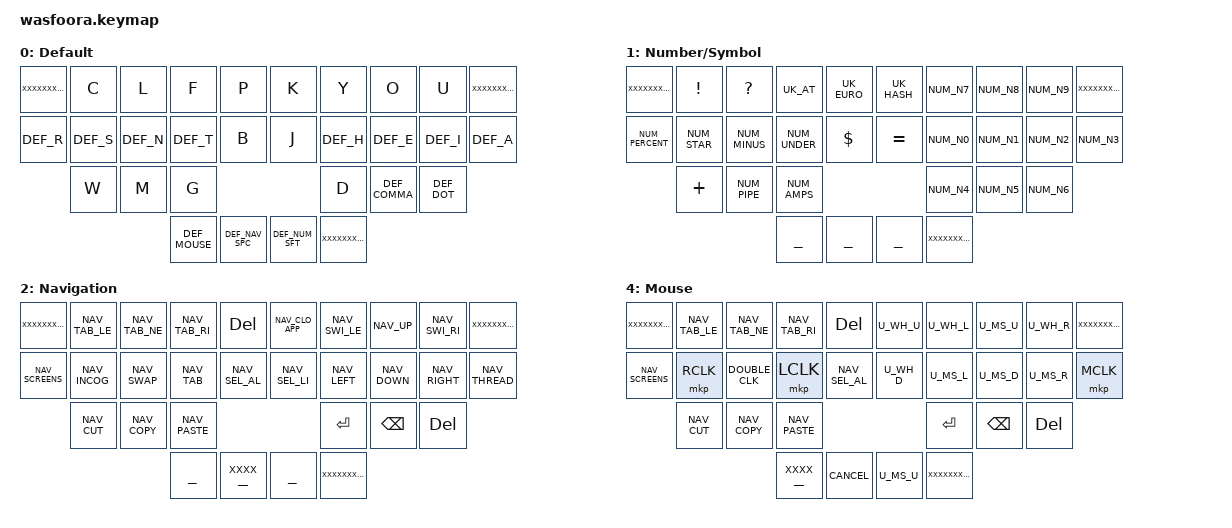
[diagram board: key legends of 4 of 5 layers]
/*					   KEY POSITIONS
 *		 0	 1	 2	 3	 4		 5	 6	 7	 8	 9
 *		10	11	12	13	14		15	16	17	18	19
 *			20	21	22				23	24	25
 *					26	27		28	29
 *
 *		 	 C	 L	 F	 P		 K	 Y	 O	 U
 *		 R	 S	 N	 T	 B		 J	 H	 E	 I	 A
 *			 W	 M	 G				 D	 ,	 .
 *					   SPACE   SHIFT
 *
 *          	 Q	                    ```
 *             V   QU                  `   ' 
 *		 	 C	 L	 F	 P		 K	 Y	 O	 U
 *		 R	 S	 N	 T	 B		 J	 H	 E	 I	 A
 *			 W	 M	 G				 D	 ,	 .
 *             X   Z                   \   /
 *               ?                       ?
 */

#include "defines.dtsi"
#include "combos.dtsi"
#include "behaviors.dtsi"
#include "mouse.dtsi"
#include "macros.dtsi"

// DELETE WORDS ETC?
// LEFT HAND - diagonal lower tab (on nav shift tab) / esc on upper
// RIGHT HAND - what is useful? .space shift
// right hand shift for DQT, home row bracket pairingscd
// maybe backspace word instead of tab?
// right shift and key next to it for ALT+SPACE left hand side for puntuation with auto enter capitals etc "DOT ENTER SHIFT", "COMMA" (make the one on the first layer "COMMA SPACE"), "DOT" (make the one on the first layer "DOT SPACE SHIFT")
// https://rndkbd.com/products/sprit-springs?variant=43822770847978 with Oil Kings
/ {
	keymap {
		compatible = "zmk,keymap";

		DEF_layer {
            display-name = "Default";
            bindings = <
				XXXXXXXXXX	&kp C		&kp L		&kp F		&kp P				&kp K		&kp Y		&kp O		&kp U		XXXXXXXXXX
				DEF_R		DEF_S		DEF_N		DEF_T		&kp B				&kp J		DEF_H		DEF_E		DEF_I		DEF_A
							&kp W		&kp M		&kp G										&kp D		DEF_COMMA	DEF_DOT

													DEF_MOUSE	DEF_NAV_SPC			DEF_NUM_SFT	XXXXXXXXXX
			>;
		};

        NUM_layer {
            display-name = "Number/Symbol";
			bindings = <
				XXXXXXXXXX	&kp EXCL	&kp QMARK	UK_AT		UK_EURO 			UK_HASH		NUM_N7		NUM_N8		NUM_N9		XXXXXXXXXX
				NUM_PERCENT NUM_STAR  	NUM_MINUS	NUM_UNDER	&kp DOLLAR			&kp EQUAL	NUM_N0		NUM_N1		NUM_N2		NUM_N3
							&kp PLUS  	NUM_PIPE	NUM_AMPS									NUM_N4		NUM_N5		NUM_N6

													__________	__________			__________	XXXXXXXXXX // num word
			>;
		};

        NAV_layer {
            display-name = "Navigation";
			bindings = <
				XXXXXXXXXX	NAV_TAB_LE	NAV_TAB_NE	NAV_TAB_RI	&kp DEL				NAV_CLO_APP	NAV_SWI_LE	NAV_UP		NAV_SWI_RI	XXXXXXXXXX
				NAV_SCREENS	NAV_INCOG	NAV_SWAP	NAV_TAB		NAV_SEL_AL			NAV_SEL_LI	NAV_LEFT	NAV_DOWN	NAV_RIGHT	NAV_THREAD
							NAV_CUT		NAV_COPY	NAV_PASTE									&kp ENTER 	&kp BSPC	&kp DEL 

													__________	___XXXX___			__________	XXXXXXXXXX
			>;
		};

		MIS_layer {
            display-name = "Miscellaneous";
            bindings = <
				XXXXXXXXXX	&kp C_PREV	&kp C_PLAY	&kp C_NEXT	MIS_BRI_DN			MIS_BRI_UP	MIS_VOL_DN	MIS_VOL_MU	MIS_VOL_UP	XXXXXXXXXX
				MIS_BITWAR	&kp F2		&kp F11		&kp F6		&kp F12				&bt BT_CLR	MIS_BT_1	MIS_BT_2	MIS_BT_3	MIS_GENERAT
							&soft_off	UK_TILDE	MIS_CAD										MIS_SLEEP	&kp CARET	&bootloader

													__________	___XXXX___			___XXXX___	XXXXXXXXXX
			>;
		};

		// tap = lclk, hold = ctrl + lclk
		MOU_layer {
            display-name = "Mouse";
            bindings = <
				XXXXXXXXXX	NAV_TAB_LE	NAV_TAB_NE	NAV_TAB_RI	&kp DEL				U_WH_U		U_WH_L		U_MS_U		U_WH_R		XXXXXXXXXX
				NAV_SCREENS	&mkp RCLK	DOUBLE_CLK	&mkp LCLK	NAV_SEL_AL			U_WH_D		U_MS_L		U_MS_D		U_MS_R		&mkp MCLK
							NAV_CUT		NAV_COPY	NAV_PASTE									&kp ENTER 	&kp BSPC	&kp DEL

													___XXXX___	CANCEL				U_MS_U		XXXXXXXXXX
			>;
		};
	};
};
